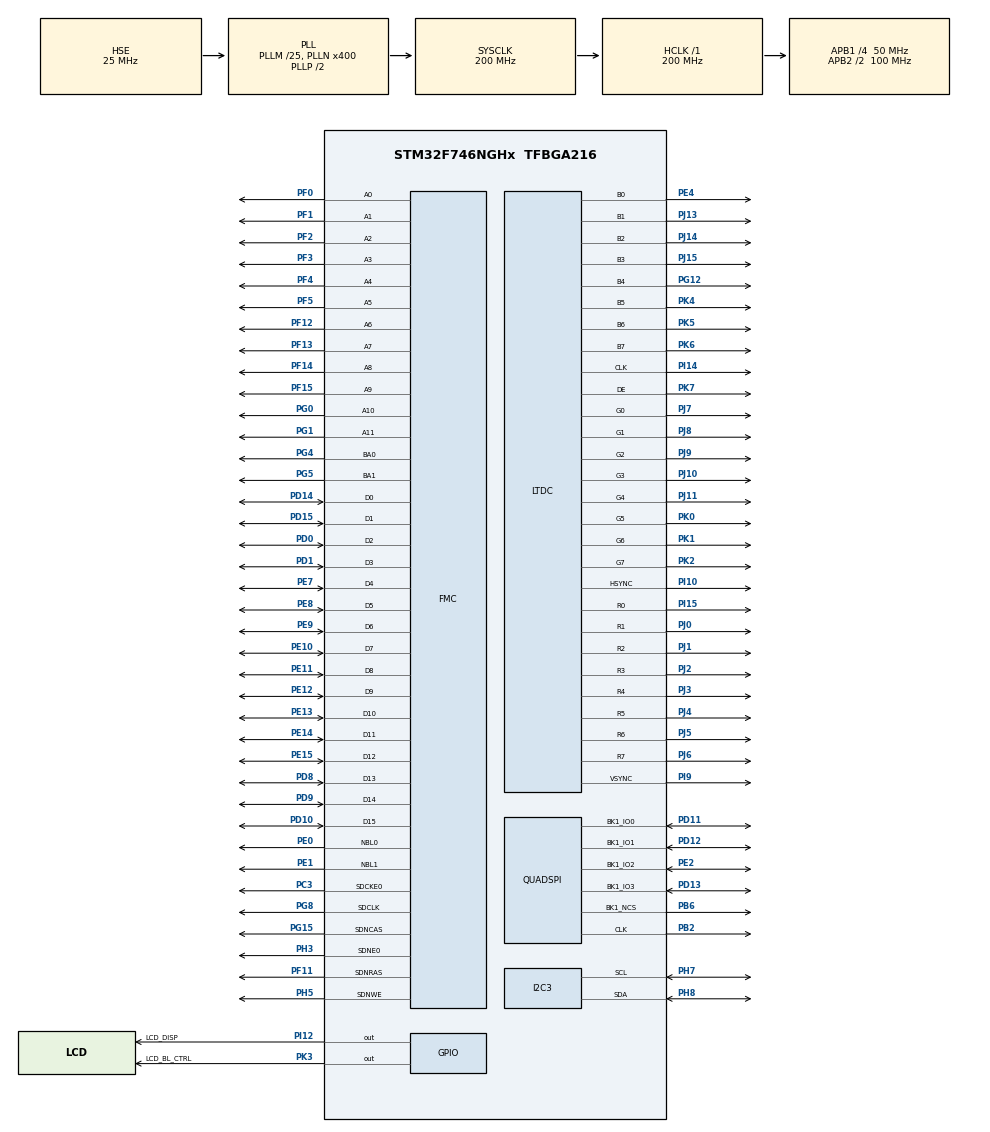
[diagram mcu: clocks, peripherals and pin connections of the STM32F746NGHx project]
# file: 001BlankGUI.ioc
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CORTEX_M7.ART_ACCLERATOR_ENABLE=1
CORTEX_M7.AccessPermission-Cortex_Memory_Protection_Unit_Region0_Settings=MPU_REGION_FULL_ACCESS
CORTEX_M7.AccessPermission-Cortex_Memory_Protection_Unit_Region1_Settings=MPU_REGION_FULL_ACCESS
CORTEX_M7.BaseAddress-Cortex_Memory_Protection_Unit_Region0_Settings=0x90000000
CORTEX_M7.BaseAddress-Cortex_Memory_Protection_Unit_Region1_Settings=0x90000000
CORTEX_M7.CPU_DCache=Enabled
CORTEX_M7.CPU_ICache=Enabled
CORTEX_M7.Enable-Cortex_Memory_Protection_Unit_Region0_Settings=MPU_REGION_ENABLE
CORTEX_M7.Enable-Cortex_Memory_Protection_Unit_Region1_Settings=MPU_REGION_ENABLE
CORTEX_M7.IsCacheable-Cortex_Memory_Protection_Unit_Region1_Settings=MPU_ACCESS_CACHEABLE
CORTEX_M7.MPU_Control=MPU_PRIVILEGED_DEFAULT
CORTEX_M7.PREFETCH_ENABLE=1
CORTEX_M7.Size-Cortex_Memory_Protection_Unit_Region0_Settings=MPU_REGION_SIZE_256MB
CORTEX_M7.Size-Cortex_Memory_Protection_Unit_Region1_Settings=MPU_REGION_SIZE_16MB
FMC.CASLatency1=FMC_SDRAM_CAS_LATENCY_3
FMC.ExitSelfRefreshDelay1=7
FMC.LoadToActiveDelay1=2
FMC.RCDDelay1=2
FMC.RPDelay1=2
FMC.ReadBurst1=FMC_SDRAM_RBURST_ENABLE
FMC.RowCycleDelay1=7
FMC.SDClockPeriod1=FMC_SDRAM_CLOCK_PERIOD_2
FMC.SelfRefreshTime1=4
FMC.WriteRecoveryTime1=3
FREERTOS.Tasks01=defaultTask,24,128,StartDefaultTask,Default,NULL,Dynamic,NULL,NULL;TouchGFXTask,24,4096,TouchGFX_Task,As external,NULL,Dynamic,NULL,NULL
FREERTOS.configTOTAL_HEAP_SIZE=32768
FREERTOS.configUSE_APPLICATION_TASK_TAG=1
FREERTOS.configUSE_IDLE_HOOK=1
FREERTOS.configUSE_NEWLIB_REENTRANT=1
I2C3.Timing=0x00C0EAFF
LTDC.ActiveH=272
LTDC.ActiveW=480
LTDC.Alpha_L0=255
LTDC.FBStartAdress_L0=0xC0000000
LTDC.HBP=13
LTDC.HFP=32
LTDC.HSync=41
LTDC.ImageHeight_L0=272
LTDC.ImageWidth_L0=480
LTDC.Layers=0
LTDC.PixelFormat_L0=LTDC_PIXEL_FORMAT_RGB565
LTDC.VSync=10
LTDC.WindowX1_L0=480
LTDC.WindowY1_L0=272
Mcu.Family=STM32F7
Mcu.Name=STM32F746NGHx
Mcu.Package=TFBGA216
NVIC.DMA2D_IRQn=true\:5\:0\:true\:false\:true\:true\:true\:true
NVIC.LTDC_IRQn=true\:5\:0\:true\:false\:true\:true\:true\:true
NVIC.PriorityGroup=NVIC_PRIORITYGROUP_4
NVIC.TIM6_DAC_IRQn=true\:0\:0\:false\:false\:true\:false\:false\:true
NVIC.TimeBase=TIM6_DAC_IRQn
NVIC.TimeBaseIP=TIM6
PA13.Mode=Serial_Wire
PA13.Signal=SYS_JTMS-SWDIO
PA14.Mode=Serial_Wire
PA14.Signal=SYS_JTCK-SWCLK
PB2.Mode=Single Bank 1
PB2.Signal=QUADSPI_CLK
PB6.Mode=Single Bank 1
PB6.Signal=QUADSPI_BK1_NCS
PC3.Mode=SdramChipSelect1_1
PC3.Signal=FMC_SDCKE0
PD0.Signal=FMC_D2_DA2
PD1.Signal=FMC_D3_DA3
PD10.Signal=FMC_D15_DA15
PD11.Mode=Single Bank 1
PD11.Signal=QUADSPI_BK1_IO0
PD12.Mode=Single Bank 1
PD12.Signal=QUADSPI_BK1_IO1
PD13.Mode=Single Bank 1
PD13.Signal=QUADSPI_BK1_IO3
PD14.Signal=FMC_D0_DA0
PD15.Signal=FMC_D1_DA1
PD8.Signal=FMC_D13_DA13
PD9.Signal=FMC_D14_DA14
PE0.Signal=FMC_NBL0
PE1.Signal=FMC_NBL1
PE10.Signal=FMC_D7_DA7
PE11.Signal=FMC_D8_DA8
PE12.Signal=FMC_D9_DA9
PE13.Signal=FMC_D10_DA10
PE14.Signal=FMC_D11_DA11
PE15.Signal=FMC_D12_DA12
PE2.Mode=Single Bank 1
PE2.Signal=QUADSPI_BK1_IO2
PE4.Mode=RGB888
PE4.Signal=LTDC_B0
PE7.Signal=FMC_D4_DA4
PE8.Signal=FMC_D5_DA5
PE9.Signal=FMC_D6_DA6
PF0.Signal=FMC_A0
PF1.Signal=FMC_A1
PF11.Signal=FMC_SDNRAS
PF12.Signal=FMC_A6
PF13.Signal=FMC_A7
PF14.Signal=FMC_A8
PF15.Signal=FMC_A9
PF2.Signal=FMC_A2
PF3.Signal=FMC_A3
PF4.Signal=FMC_A4
PF5.Signal=FMC_A5
PG0.Signal=FMC_A10
PG1.Signal=FMC_A11
PG12.Mode=RGB888
PG12.Signal=LTDC_B4
PG15.Signal=FMC_SDNCAS
PG4.Signal=FMC_A14_BA0
PG5.Signal=FMC_A15_BA1
PG8.Signal=FMC_SDCLK
PH0/OSC_IN.Mode=HSE-External-Oscillator
PH0/OSC_IN.Signal=RCC_OSC_IN
PH1/OSC_OUT.Mode=HSE-External-Oscillator
PH1/OSC_OUT.Signal=RCC_OSC_OUT
PH3.Mode=SdramChipSelect1_1
PH3.Signal=FMC_SDNE0
PH5.Signal=FMC_SDNWE
PH7.GPIO_Pu=GPIO_PULLUP
PH7.Mode=I2C
PH7.Signal=I2C3_SCL
PH8.GPIO_Pu=GPIO_PULLUP
PH8.Mode=I2C
PH8.Signal=I2C3_SDA
PI10.Mode=RGB888
PI10.Signal=LTDC_HSYNC
PI12.GPIO_Label=LCD_DISP
PI12.PinState=GPIO_PIN_SET
PI12.Signal=GPIO_Output
PI14.Mode=RGB888
PI14.Signal=LTDC_CLK
PI15.Mode=RGB888
PI15.Signal=LTDC_R0
PI9.Mode=RGB888
PI9.Signal=LTDC_VSYNC
PJ0.Mode=RGB888
PJ0.Signal=LTDC_R1
PJ1.Mode=RGB888
PJ1.Signal=LTDC_R2
PJ10.Mode=RGB888
PJ10.Signal=LTDC_G3
PJ11.Mode=RGB888
PJ11.Signal=LTDC_G4
PJ13.Mode=RGB888
PJ13.Signal=LTDC_B1
PJ14.Mode=RGB888
PJ14.Signal=LTDC_B2
PJ15.Mode=RGB888
PJ15.Signal=LTDC_B3
PJ2.Mode=RGB888
PJ2.Signal=LTDC_R3
PJ3.Mode=RGB888
PJ3.Signal=LTDC_R4
PJ4.Mode=RGB888
PJ4.Signal=LTDC_R5
PJ5.Mode=RGB888
PJ5.Signal=LTDC_R6
PJ6.Mode=RGB888
PJ6.Signal=LTDC_R7
PJ7.Mode=RGB888
PJ7.Signal=LTDC_G0
PJ8.Mode=RGB888
PJ8.Signal=LTDC_G1
PJ9.Mode=RGB888
PJ9.Signal=LTDC_G2
PK0.Mode=RGB888
PK0.Signal=LTDC_G5
PK1.Mode=RGB888
PK1.Signal=LTDC_G6
PK2.Mode=RGB888
PK2.Signal=LTDC_G7
PK3.GPIO_Label=LCD_BL_CTRL
PK3.PinState=GPIO_PIN_SET
PK3.Signal=GPIO_Output
PK4.Mode=RGB888
PK4.Signal=LTDC_B5
PK5.Mode=RGB888
PK5.Signal=LTDC_B6
PK6.Mode=RGB888
PK6.Signal=LTDC_B7
PK7.Mode=RGB888
PK7.Signal=LTDC_DE
ProjectManager.HeapSize=0xA00
ProjectManager.StackSize=0xA00
ProjectManager.TargetToolchain=STM32CubeIDE
QUADSPI.ChipSelectHighTime=QSPI_CS_HIGH_TIME_6_CYCLE
QUADSPI.ClockPrescaler=1
QUADSPI.FifoThreshold=4
QUADSPI.FlashSize=24
QUADSPI.SampleShifting=QSPI_SAMPLE_SHIFTING_HALFCYCLE
RCC.AHBFreq_Value=200000000
RCC.APB1CLKDivider=RCC_HCLK_DIV4
RCC.APB1Freq_Value=50000000
RCC.APB1TimFreq_Value=100000000
RCC.APB2CLKDivider=RCC_HCLK_DIV2
RCC.APB2Freq_Value=100000000
RCC.APB2TimFreq_Value=200000000
RCC.CortexFreq_Value=200000000
RCC.HCLKFreq_Value=200000000
RCC.HSE_VALUE=25000000
RCC.HSI_VALUE=16000000
RCC.LSE_VALUE=32768
RCC.PLLI2SN=100
RCC.PLLM=25
RCC.PLLN=400
RCC.PLLSAIN=384
RCC.PLLSAIR=5
RCC.PLLSAIRDiv=RCC_PLLSAIDIVR_8
RCC.PLLSourceVirtual=RCC_PLLSOURCE_HSE
RCC.SYSCLKFreq_VALUE=200000000
RCC.SYSCLKSource=RCC_SYSCLKSOURCE_PLLCLK
RCC.USBFreq_Value=200000000
RCC.VCOOutputFreq_Value=400000000
SH.FMC_A0.0=FMC_A0,12b-sda1
SH.FMC_A1.0=FMC_A1,12b-sda1
SH.FMC_A10.0=FMC_A10,12b-sda1
SH.FMC_A11.0=FMC_A11,12b-sda1
SH.FMC_A14_BA0.0=FMC_BA0,FourSdramBanks1
SH.FMC_A15_BA1.0=FMC_BA1,FourSdramBanks1
SH.FMC_A2.0=FMC_A2,12b-sda1
SH.FMC_A3.0=FMC_A3,12b-sda1
SH.FMC_A4.0=FMC_A4,12b-sda1
SH.FMC_A5.0=FMC_A5,12b-sda1
SH.FMC_A6.0=FMC_A6,12b-sda1
SH.FMC_A7.0=FMC_A7,12b-sda1
SH.FMC_A8.0=FMC_A8,12b-sda1
SH.FMC_A9.0=FMC_A9,12b-sda1
SH.FMC_D0_DA0.0=FMC_D0,sd-16b-d1
SH.FMC_D10_DA10.0=FMC_D10,sd-16b-d1
SH.FMC_D11_DA11.0=FMC_D11,sd-16b-d1
SH.FMC_D12_DA12.0=FMC_D12,sd-16b-d1
SH.FMC_D13_DA13.0=FMC_D13,sd-16b-d1
SH.FMC_D14_DA14.0=FMC_D14,sd-16b-d1
SH.FMC_D15_DA15.0=FMC_D15,sd-16b-d1
SH.FMC_D1_DA1.0=FMC_D1,sd-16b-d1
SH.FMC_D2_DA2.0=FMC_D2,sd-16b-d1
SH.FMC_D3_DA3.0=FMC_D3,sd-16b-d1
SH.FMC_D4_DA4.0=FMC_D4,sd-16b-d1
SH.FMC_D5_DA5.0=FMC_D5,sd-16b-d1
SH.FMC_D6_DA6.0=FMC_D6,sd-16b-d1
SH.FMC_D7_DA7.0=FMC_D7,sd-16b-d1
SH.FMC_D8_DA8.0=FMC_D8,sd-16b-d1
SH.FMC_D9_DA9.0=FMC_D9,sd-16b-d1
SH.FMC_NBL0.0=FMC_NBL0,Sd2ByteEnable1
SH.FMC_NBL1.0=FMC_NBL1,Sd2ByteEnable1
SH.FMC_SDCLK.0=FMC_SDCLK,12b-sda1
SH.FMC_SDNCAS.0=FMC_SDNCAS,12b-sda1
SH.FMC_SDNRAS.0=FMC_SDNRAS,12b-sda1
SH.FMC_SDNWE.0=FMC_SDNWE,12b-sda1
STMicroelectronics.X-CUBE-TOUCHGFX.4.17.0.ApplicationCcGraphicsJjApplication=TouchGFXOoGenerator
STMicroelectronics.X-CUBE-TOUCHGFX.4.17.0.tgfx_address1=0xC0000000
STMicroelectronics.X-CUBE-TOUCHGFX.4.17.0.tgfx_address2=0xC003FC00
STMicroelectronics.X-CUBE-TOUCHGFX.4.17.0.tgfx_buffering_strategy=Double
STMicroelectronics.X-CUBE-TOUCHGFX.4.17.0.tgfx_display_interface=disp_ltdc
STMicroelectronics.X-CUBE-TOUCHGFX.4.17.0.tgfx_hardware_accelerator=dma_2d
STMicroelectronics.X-CUBE-TOUCHGFX.4.17.0.tgfx_location=By Address
STMicroelectronics.X-CUBE-TOUCHGFX.4.17.0.tgfx_vsync=vsync_ltdc
VP_CRC_VS_CRC.Mode=CRC_Activate
VP_DMA2D_VS_DMA2D.Mode=DMA2D_Activate
VP_FREERTOS_VS_CMSIS_V2.Mode=CMSIS_V2
VP_STMicroelectronics.X-CUBE-TOUCHGFX_VS_GraphicsJjApplication_4.17.0.Mode=GraphicsJjApplication
VP_SYS_VS_tim6.Mode=TIM6
board=custom

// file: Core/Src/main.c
/* USER CODE BEGIN Header */
/**
  ******************************************************************************
  * @file           : main.c
  * @brief          : Main program body
  ******************************************************************************
  * @attention
  *
  * <h2><center>&copy; Copyright (c) 2020 STMicroelectronics.
  * All rights reserved.</center></h2>
  *
  * This software component is licensed by ST under Ultimate Liberty license
  * SLA0044, the "License"; You may not use this file except in compliance with
  * the License. You may obtain a copy of the License at:
  *                             www.st.com/SLA0044
  *
  ******************************************************************************
  */
/* USER CODE END Header */
#include "main.h"
#include "cmsis_os.h"
#include "crc.h"
#include "dma2d.h"
#include "i2c.h"
#include "ltdc.h"
#include "quadspi.h"
#include "gpio.h"
#include "fmc.h"
#include "app_touchgfx.h"

/* USER CODE BEGIN Includes */
#include <stm32746g_discovery_qspi.h>
/* USER CODE END Includes */

/* USER CODE BEGIN PD */

#define REFRESH_COUNT        1835

#define SDRAM_TIMEOUT                            ((uint32_t)0xFFFF)
#define SDRAM_MODEREG_BURST_LENGTH_1             ((uint16_t)0x0000)
#define SDRAM_MODEREG_BURST_LENGTH_2             ((uint16_t)0x0001)
#define SDRAM_MODEREG_BURST_LENGTH_4             ((uint16_t)0x0002)
#define SDRAM_MODEREG_BURST_LENGTH_8             ((uint16_t)0x0004)
#define SDRAM_MODEREG_BURST_TYPE_SEQUENTIAL      ((uint16_t)0x0000)
#define SDRAM_MODEREG_BURST_TYPE_INTERLEAVED     ((uint16_t)0x0008)
#define SDRAM_MODEREG_CAS_LATENCY_2              ((uint16_t)0x0020)
#define SDRAM_MODEREG_CAS_LATENCY_3              ((uint16_t)0x0030)
#define SDRAM_MODEREG_OPERATING_MODE_STANDARD    ((uint16_t)0x0000)
#define SDRAM_MODEREG_WRITEBURST_MODE_PROGRAMMED ((uint16_t)0x0000)
#define SDRAM_MODEREG_WRITEBURST_MODE_SINGLE     ((uint16_t)0x0200)

/* USER CODE END PD */

/* USER CODE BEGIN PV */
static FMC_SDRAM_CommandTypeDef Command;
/* USER CODE END PV */

void SystemClock_Config(void);
static void MPU_Config(void);
void MX_FREERTOS_Init(void);

int main(void)
{

  /* MPU Configuration--------------------------------------------------------*/
  MPU_Config();

  /* Enable I-Cache---------------------------------------------------------*/
  SCB_EnableICache();

  /* Enable D-Cache---------------------------------------------------------*/
  SCB_EnableDCache();

  /* MCU Configuration--------------------------------------------------------*/

  /* Reset of all peripherals, Initializes the Flash interface and the Systick. */
  HAL_Init();

  /* Configure the system clock */
  SystemClock_Config();

  /* Initialize all configured peripherals */
  MX_GPIO_Init();
  MX_CRC_Init();
  MX_DMA2D_Init();
  MX_FMC_Init();
  MX_I2C3_Init();
  MX_LTDC_Init();
  MX_QUADSPI_Init();
  MX_TouchGFX_Init();

  /* Init scheduler */
  osKernelInitialize();  /* Call init function for freertos objects (in freertos.c) */
  MX_FREERTOS_Init();
  /* Start scheduler */
  osKernelStart();

  /* We should never get here as control is now taken by the scheduler */
  /* Infinite loop */
  while (1)
  {

  }
}

void SystemClock_Config(void)
{
  RCC_OscInitTypeDef RCC_OscInitStruct = {0};
  RCC_ClkInitTypeDef RCC_ClkInitStruct = {0};
  RCC_PeriphCLKInitTypeDef PeriphClkInitStruct = {0};

  /** Configure the main internal regulator output voltage
  */
  __HAL_RCC_PWR_CLK_ENABLE();
  __HAL_PWR_VOLTAGESCALING_CONFIG(PWR_REGULATOR_VOLTAGE_SCALE1);
  /** Initializes the RCC Oscillators according to the specified parameters
  * in the RCC_OscInitTypeDef structure.
  */
  RCC_OscInitStruct.OscillatorType = RCC_OSCILLATORTYPE_HSE;
  RCC_OscInitStruct.HSEState = RCC_HSE_ON;
  RCC_OscInitStruct.PLL.PLLState = RCC_PLL_ON;
  RCC_OscInitStruct.PLL.PLLSource = RCC_PLLSOURCE_HSE;
  RCC_OscInitStruct.PLL.PLLM = 25;
  RCC_OscInitStruct.PLL.PLLN = 400;
  RCC_OscInitStruct.PLL.PLLP = RCC_PLLP_DIV2;
  RCC_OscInitStruct.PLL.PLLQ = 2;
  if (HAL_RCC_OscConfig(&RCC_OscInitStruct) != HAL_OK)
  {
    Error_Handler();
  }
  /** Activate the Over-Drive mode
  */
  if (HAL_PWREx_EnableOverDrive() != HAL_OK)
  {
    Error_Handler();
  }
  /** Initializes the CPU, AHB and APB buses clocks
  */
  RCC_ClkInitStruct.ClockType = RCC_CLOCKTYPE_HCLK|RCC_CLOCKTYPE_SYSCLK
                              |RCC_CLOCKTYPE_PCLK1|RCC_CLOCKTYPE_PCLK2;
  RCC_ClkInitStruct.SYSCLKSource = RCC_SYSCLKSOURCE_PLLCLK;
  RCC_ClkInitStruct.AHBCLKDivider = RCC_SYSCLK_DIV1;
  RCC_ClkInitStruct.APB1CLKDivider = RCC_HCLK_DIV4;
  RCC_ClkInitStruct.APB2CLKDivider = RCC_HCLK_DIV2;

  if (HAL_RCC_ClockConfig(&RCC_ClkInitStruct, FLASH_LATENCY_6) != HAL_OK)
  {
    Error_Handler();
  }
  PeriphClkInitStruct.PeriphClockSelection = RCC_PERIPHCLK_LTDC|RCC_PERIPHCLK_I2C3;
  PeriphClkInitStruct.PLLSAI.PLLSAIN = 384;
  PeriphClkInitStruct.PLLSAI.PLLSAIR = 5;
  PeriphClkInitStruct.PLLSAI.PLLSAIQ = 2;
  PeriphClkInitStruct.PLLSAI.PLLSAIP = RCC_PLLSAIP_DIV2;
  PeriphClkInitStruct.PLLSAIDivQ = 1;
  PeriphClkInitStruct.PLLSAIDivR = RCC_PLLSAIDIVR_8;
  PeriphClkInitStruct.I2c3ClockSelection = RCC_I2C3CLKSOURCE_PCLK1;
  if (HAL_RCCEx_PeriphCLKConfig(&PeriphClkInitStruct) != HAL_OK)
  {
    Error_Handler();
  }
}

/* MPU Configuration */

void MPU_Config(void)
{
  MPU_Region_InitTypeDef MPU_InitStruct = {0};

  /* Disables the MPU */
  HAL_MPU_Disable();
  /** Initializes and configures the Region and the memory to be protected
  */
  MPU_InitStruct.Enable = MPU_REGION_ENABLE;
  MPU_InitStruct.Number = MPU_REGION_NUMBER0;
  MPU_InitStruct.BaseAddress = 0x90000000;
  MPU_InitStruct.Size = MPU_REGION_SIZE_256MB;
  MPU_InitStruct.SubRegionDisable = 0x0;
  MPU_InitStruct.TypeExtField = MPU_TEX_LEVEL0;
  MPU_InitStruct.AccessPermission = MPU_REGION_FULL_ACCESS;
  MPU_InitStruct.DisableExec = MPU_INSTRUCTION_ACCESS_ENABLE;
  MPU_InitStruct.IsShareable = MPU_ACCESS_NOT_SHAREABLE;
  MPU_InitStruct.IsCacheable = MPU_ACCESS_NOT_CACHEABLE;
  MPU_InitStruct.IsBufferable = MPU_ACCESS_NOT_BUFFERABLE;

  HAL_MPU_ConfigRegion(&MPU_InitStruct);
  /** Initializes and configures the Region and the memory to be protected
  */
  MPU_InitStruct.Number = MPU_REGION_NUMBER1;
  MPU_InitStruct.Size = MPU_REGION_SIZE_16MB;
  MPU_InitStruct.IsCacheable = MPU_ACCESS_CACHEABLE;

  HAL_MPU_ConfigRegion(&MPU_InitStruct);
  /* Enables the MPU */
  HAL_MPU_Enable(MPU_PRIVILEGED_DEFAULT);

}

void HAL_TIM_PeriodElapsedCallback(TIM_HandleTypeDef *htim)
{
  if (htim->Instance == TIM6) {
    HAL_IncTick();
  }
}

void Error_Handler(void)
{
}

/************************ (C) COPYRIGHT STMicroelectronics *****END OF FILE****/

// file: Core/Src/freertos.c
/* USER CODE BEGIN Header */
/**
  ******************************************************************************
  * File Name          : freertos.c
  * Description        : Code for freertos applications
  ******************************************************************************
  * @attention
  *
  * <h2><center>&copy; Copyright (c) 2021 STMicroelectronics.
  * All rights reserved.</center></h2>
  *
  * This software component is licensed by ST under Ultimate Liberty license
  * SLA0044, the "License"; You may not use this file except in compliance with
  * the License. You may obtain a copy of the License at:
  *                             www.st.com/SLA0044
  *
  ******************************************************************************
  */
/* USER CODE END Header */

#include "FreeRTOS.h"
#include "task.h"
#include "main.h"
#include "cmsis_os.h"

/* Definitions for defaultTask */
osThreadId_t defaultTaskHandle;
const osThreadAttr_t defaultTask_attributes = {
  .name = "defaultTask",
  .stack_size = 128 * 4,
  .priority = (osPriority_t) osPriorityNormal,
};
/* Definitions for TouchGFXTask */
osThreadId_t TouchGFXTaskHandle;
const osThreadAttr_t TouchGFXTask_attributes = {
  .name = "TouchGFXTask",
  .stack_size = 4096 * 4,
  .priority = (osPriority_t) osPriorityNormal,
};

void StartDefaultTask(void *argument);
extern void TouchGFX_Task(void *argument);

void MX_FREERTOS_Init(void); /* (MISRA C 2004 rule 8.1) */

/* Hook prototypes */
void vApplicationIdleHook(void);

/* USER CODE BEGIN 2 */
__weak void vApplicationIdleHook( void )
{
   /* vApplicationIdleHook() will only be called if configUSE_IDLE_HOOK is set
   to 1 in FreeRTOSConfig.h. It will be called on each iteration of the idle
   task. It is essential that code added to this hook function never attempts
   to block in any way (for example, call xQueueReceive() with a block time
   specified, or call vTaskDelay()). If the application makes use of the
   vTaskDelete() API function (as this demo application does) then it is also
   important that vApplicationIdleHook() is permitted to return to its calling
   function, because it is the responsibility of the idle task to clean up
   memory allocated by the kernel to any task that has since been deleted. */
}
/* USER CODE END 2 */

void MX_FREERTOS_Init(void) {

  /* Create the thread(s) */
  /* creation of defaultTask */
  defaultTaskHandle = osThreadNew(StartDefaultTask, NULL, &defaultTask_attributes);

  /* creation of TouchGFXTask */
  TouchGFXTaskHandle = osThreadNew(TouchGFX_Task, NULL, &TouchGFXTask_attributes);

}

void StartDefaultTask(void *argument)
{
  for(;;)
  {
    osDelay(1);
  }
}

/************************ (C) COPYRIGHT STMicroelectronics *****END OF FILE****/
